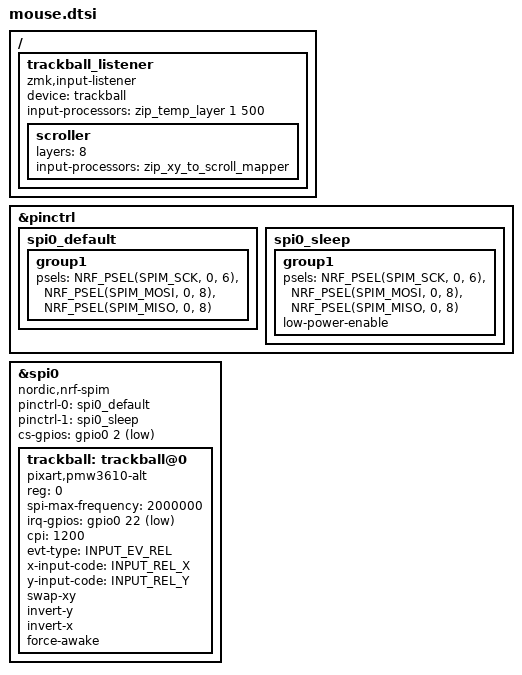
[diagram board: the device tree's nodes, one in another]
#include <dt-bindings/gpio/gpio.h>
#include <zephyr/dt-bindings/pinctrl/nrf-pinctrl.h>
#include <zephyr/dt-bindings/input/input-event-codes.h>
#include <input/processors.dtsi>

/ {
    trackball_listener: trackball_listener {
        compatible = "zmk,input-listener";
        device = <&trackball>;
        input-processors = <&zip_temp_layer 1 500>;

        scroller {
            layers = <8>;  // LAYER_MEDIA - change to whichever layer you pick
            input-processors = <&zip_xy_to_scroll_mapper>;
        };
    };
};

&pinctrl {
    spi0_default: spi0_default {
        group1 {
            psels = <NRF_PSEL(SPIM_SCK, 0, 6)>,
                    <NRF_PSEL(SPIM_MOSI, 0, 8)>,
                    <NRF_PSEL(SPIM_MISO, 0, 8)>;
        };
    };

    spi0_sleep: spi0_sleep {
        group1 {
            psels = <NRF_PSEL(SPIM_SCK, 0, 6)>,
                    <NRF_PSEL(SPIM_MOSI, 0, 8)>,
                    <NRF_PSEL(SPIM_MISO, 0, 8)>;
            low-power-enable;
        };
    };
};

&spi0 {
    status = "okay";
    compatible = "nordic,nrf-spim";
    pinctrl-0 = <&spi0_default>;
    pinctrl-1 = <&spi0_sleep>;
    pinctrl-names = "default", "sleep";
    cs-gpios = <&gpio0 2 GPIO_ACTIVE_LOW>;

    trackball: trackball@0 {
        status = "okay";
        compatible = "pixart,pmw3610-alt";
        reg = <0>;
        spi-max-frequency = <2000000>;
        irq-gpios = <&gpio0 22 (GPIO_ACTIVE_LOW | GPIO_PULL_UP)>;

        cpi = <1200>;

        evt-type = <INPUT_EV_REL>;
        x-input-code = <INPUT_REL_X>;
        y-input-code = <INPUT_REL_Y>;
        swap-xy;
        invert-y;
        invert-x;

        force-awake;
        // force-awake-4ms-mode; not recommended for wireless
    };
};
